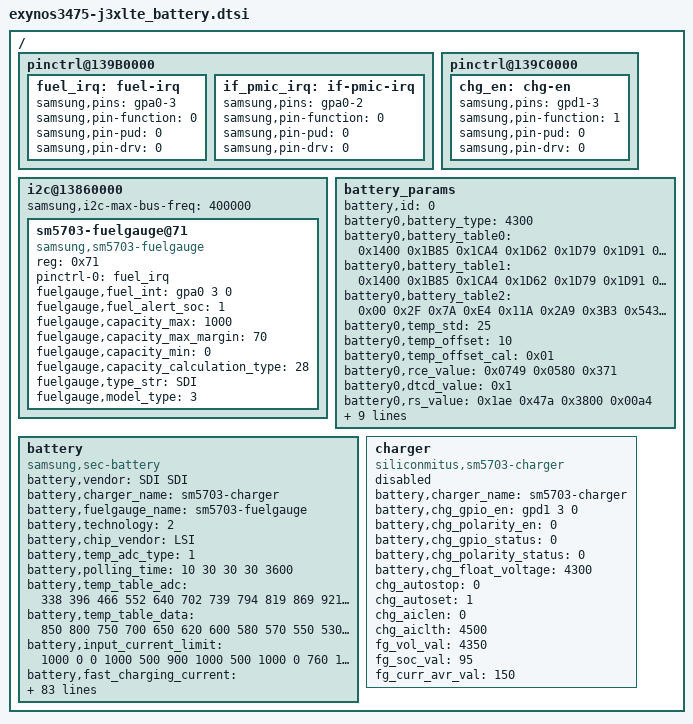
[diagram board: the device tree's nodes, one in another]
/*
 * SAMSUNG UNIVERSAL3475 board device tree source
 *
 * Copyright (c) 2015 Samsung Electronics Co., Ltd.
 *		http://www.samsung.com
 *
 * This program is free software; you can redistribute it and/or modify
 * it under the terms of the GNU General Public License version 2 as
 * published by the Free Software Foundation.
*/

/ {
	pinctrl@139B0000 {
		fuel_irq: fuel-irq {
			samsung,pins = "gpa0-3";
			samsung,pin-function = <0>;
			samsung,pin-pud = <0>;
			samsung,pin-drv = <0>;
		};
	};

	pinctrl@139B0000 {
		if_pmic_irq: if-pmic-irq {
			samsung,pins = "gpa0-2";
			samsung,pin-function = <0>;
			samsung,pin-pud = <0>;
			samsung,pin-drv = <0>;
		};
	};

	pinctrl@139C0000 {
		chg_en: chg-en {
			samsung,pins = "gpd1-3";
			samsung,pin-function = <1>;
			samsung,pin-pud = <0>;
			samsung,pin-drv = <0>;
		};
	};

	i2c@13860000 {
		status = "okay";
		samsung,i2c-max-bus-freq = <400000>;
		sm5703-fuelgauge@71 {
			compatible = "samsung,sm5703-fuelgauge";
			reg = <0x71>;
			pinctrl-names = "default";
			pinctrl-0 = <&fuel_irq>;
			fuelgauge,fuel_int = <&gpa0 3 0>;
			fuelgauge,fuel_alert_soc = <1>;
			fuelgauge,capacity_max = <1000>;
			fuelgauge,capacity_max_margin = <70>;
			fuelgauge,capacity_min = <0>;
			fuelgauge,capacity_calculation_type = <28>;
			fuelgauge,type_str = "SDI";
			fuelgauge,model_type = <3>;
		};
	};

	battery_params {
		battery,id = <0>; /* -1 means auto, detected by F/G */
		battery0,battery_type = <4300>; /* 4200 4350 4400 */
		battery0,battery_table0 = <0x1400 0x1B85 0x1CA4 0x1D62 0x1D79 0x1D91 0x1DED 0x1E28 0x1EBE 0x1EBE 0x1F2B 0x1FD6 0x2060 0x20B4 0x21DF 0x2400>;
		battery0,battery_table1 = <0x1400 0x1B85 0x1CA4 0x1D62 0x1D79 0x1D91 0x1DED 0x1E28 0x1EBE 0x1EBE 0x1F2B 0x1FD6 0x2060 0x20B4 0x21DF 0x2400>;
		battery0,battery_table2 = <0x00 0x2F 0x7A 0xE4 0x11A 0x2A9 0x3B3 0x543 0xAFB 0xAFB 0xC05 0xF24 0x102E 0x1138 0x1407 0x1412>;
		battery0,temp_std = <25>;
		battery0,temp_offset = <10>;
		battery0,temp_offset_cal = <0x01>;
		battery0,rce_value = <0x0749 0x0580 0x371>;
		battery0,dtcd_value = <0x1>;
		battery0,rs_value = <0x1ae 0x47a 0x3800 0x00a4>; /*rs mix_factor max min*/
		battery0,vit_period = <0x350a>;
		battery0,mix_value = <0x0503 0x0004>; /*mix_rate init_blank*/
		battery0,topoff_soc = <0x0 0x05>; /*disable soc*/
		battery0,tem_poff = <3390 100 3300 80>;
		battery0,volt_cal = <0x809E>;
		battery0,curr_cal = <0x7685>;
		battery0,charge_offset_cal = <0x05>;
		battery0,v_max_table = <0x21DF 0x21BA 0x2194>;
		battery0,q_max_table = <0x1407 0x13B0 0x1359>;
	};

	battery {
		status = "okay";

		pinctrl-names = "default";

		compatible = "samsung,sec-battery";
		battery,vendor = "SDI SDI";
		battery,charger_name = "sm5703-charger";
		battery,fuelgauge_name = "sm5703-fuelgauge";
		battery,technology = <2>; /* POWER_SUPPLY_TECHNOLOGY_LION */
		/* .temp_cohot = -1000; */
		/* .temp_cocold = -4325; */

		battery,chip_vendor = "LSI";
		battery,temp_adc_type = <1>; /* SEC_BATTERY_ADC_TYPE_AP */

		battery,polling_time = <10 30 30 30 3600>;

		battery,temp_table_adc = <338 396 466 552 640 702 739 794 819 869 921 977 1053 1111 1188 1365 1568 1774 2002
								2273 2502 2727 2820 2946 3008 3132 3162 3198 3278 3349 3413 3494 3621 3720>;

		battery,temp_table_data = <850 800 750 700 650 620 600 580 570 550 530 510 490 470 450 400 350 300 250
								200 150 100 80 50 30 10 0 (-10) (-30) (-50) (-70) (-100) (-150) (-200)>;

		battery,input_current_limit = <1000 0 0 1000 500 900 1000 500 1000 0 760 1000 1000 0 0 400 700 1000 300 1000 1000 0 1000 1000 1000 80 1000 1000 1000 450>;
		battery,fast_charging_current = <1500 0 0 1500 500 1500 1500 500 1500 0 1500 1500 1500 0 0 400 1500 1500 300 1500 1500 0 1500 1500 1500 80 1500 1500 1500 450>;
		battery,full_check_current_1st = <250 0 0 250 250 250 250 250 250 0 250 250 250 0 0 250 250 250 250 250 250 0 250 250 250 0 250 250 250 250>;
		battery,full_check_current_2nd = <125 0 0 125 125 125 125 125 125 0 125 125 125 0 0 125 125 125 125 125 125 0 125 125 125 125 125 125 125 125>;

		battery,adc_check_count = <5>;

		battery,cable_check_type = <4>; /* SEC_BATTERY_CABLE_CHECK_PSY */
		battery,cable_source_type = <1>; /* SEC_BATTERY_CABLE_SOURCE_EXTERNAL */
		battery,event_waiting_time = <600>;
		battery,polling_type = <1>; /* SEC_BATTERY_MONITOR_ALARM */
		battery,monitor_initial_count = <0>;

		battery,battery_check_type = <6>; /* SEC_BATTERY_CHECK_INT */
		battery,check_count = <0>;
		battery,bat_irq_gpio = <&gpa0 5 0>;
		battery,bat_irq_attr = <0x00002003>; /*  IRQF_TRIGGER_RISING	0x00000001
							 IRQF_TRIGGER_FALLING	0x00000002
							 IRQF_ONESHOT		0x00002000
							*/
		battery,check_adc_max = <1440>;
		battery,check_adc_min = <0>;

		battery,ovp_uvlo_check_type = <3>; /* SEC_BATTERY_OVP_UVLO_CHGPOLLING */

		battery,thermal_source = <2>; /* SEC_BATTERY_THERMAL_SOURCE_ADC */

		battery,temp_check_type = <2>; /* SEC_BATTERY_TEMP_CHECK_TEMP */
		battery,temp_check_count = <1>;
		battery,temp_highlimit_threshold_event = <800>;
		battery,temp_highlimit_recovery_event = <750>;
		battery,temp_high_threshold_event = <500>;
		battery,temp_high_recovery_event = <450>;
		battery,temp_low_threshold_event = <(0)>;
		battery,temp_low_recovery_event = <50>;
		battery,temp_highlimit_threshold_normal = <800>;
		battery,temp_highlimit_recovery_normal = <750>;
		battery,temp_high_threshold_normal = <500>;
		battery,temp_high_recovery_normal = <450>;
		battery,temp_low_threshold_normal = <(0)>;
		battery,temp_low_recovery_normal = <50>;
		battery,temp_highlimit_threshold_lpm = <800>;
		battery,temp_highlimit_recovery_lpm = <750>;
		battery,temp_high_threshold_lpm = <500>;
		battery,temp_high_recovery_lpm = <450>;
		battery,temp_low_threshold_lpm = <(-20)>;
		battery,temp_low_recovery_lpm = <40>;

		battery,full_check_type = <2>; /* SEC_BATTERY_FULLCHARGED_FG_CURRENT */
		battery,full_check_type_2nd = <2>; /* SEC_BATTERY_FULLCHARGED_FG_CURRENT */
		battery,full_check_count = <2>;
		battery,chg_gpio_full_check = <0>;
		battery,chg_polarity_full_check = <1>;

		/* SEC_BATTERY_FULL_CONDITION_SOC |
		   SEC_BATTERY_FULL_CONDITION_NOTIMEFULL |
		   SEC_BATTERY_FULL_CONDITION_VCELL */
		battery,full_condition_type = <15>;
		battery,full_condition_soc = <93>;
		battery,full_condition_vcell = <4200>;

		battery,recharge_check_count = <2>;
		battery,recharge_condition_type = <4>; /* SEC_BATTERY_RECHARGE_CONDITION_VCELL */
		battery,recharge_condition_soc = <98>;
		battery,recharge_condition_vcell = <4230>;

		battery,charging_total_time = <21600>;
		battery,recharging_total_time = <5400>;
		battery,charging_reset_time = <0>;

		battery,always_enable;

		io-channels = <&exynos_adc 0>;
		io-channel-names = "adc-temp";
		#io-channel-cells = <1>;
		io-channel-ranges;

		battery,chg_float_voltage = <4300>;

		/* battery,self_discharging_en; */
		battery,force_discharging_limit = <650>;
		battery,force_discharging_recov = <550>;
		battery,self_discharging_voltage_limit = <4250>;
		battery,discharging_adc_max = <2600>;
		battery,discharging_adc_min = <1700>;
		battery,discharging_ntc_limit = <2750>;

		battery,swelling_high_temp_block = <410>;
		battery,swelling_high_temp_recov = <390>;
		battery,swelling_low_temp_block_1st = <150>;
		battery,swelling_low_temp_recov_1st = <200>;
		battery,swelling_low_temp_block_2nd = <50>;
		battery,swelling_low_temp_recov_2nd = <100>;

		battery,swelling_low_temp_current = <760>;  // 0.3C * 3500
		battery,swelling_low_temp_topoff = <125>;  // 0.05C
		battery,swelling_high_temp_current = <760>;  // 0.45C * 3500
		battery,swelling_high_temp_topoff = <125>;  // 0.05C

		battery,swelling_drop_float_voltage = <4120>;
		battery,swelling_high_rechg_voltage = <3950>;
		battery,swelling_low_rechg_voltage = <3950>;
		battery,swelling_block_time = <600>;

		battery,standard_curr = <1500>;
		battery,expired_time = <16500>;
		battery,recharging_expired_time = <5400>;

		/* cycle(week), chg_float_voltage, recharge_condition_vcell, full_condition_vcell, full_condition_soc*/
		battery,age_data = <0 4300 4230 4200 93
				29 4280 4210 4180 91
				36 4260 4190 4160 90>;

	};

	charger {
		status = "disable";
		compatible = "siliconmitus,sm5703-charger";

		/* Charger */
		battery,charger_name = "sm5703-charger";
		battery,chg_gpio_en = <&gpd1 3 0>;
		battery,chg_polarity_en = <0>;
		battery,chg_gpio_status = <0>;
		battery,chg_polarity_status = <0>;
		battery,chg_float_voltage = <4300>;
		chg_autostop = <0>;
		chg_autoset = <1>;
		chg_aiclen = <0>;
		chg_aiclth = <4500>;
		fg_vol_val = <4350>;
		fg_soc_val = <95>;
		fg_curr_avr_val = <150>;
	};
};
